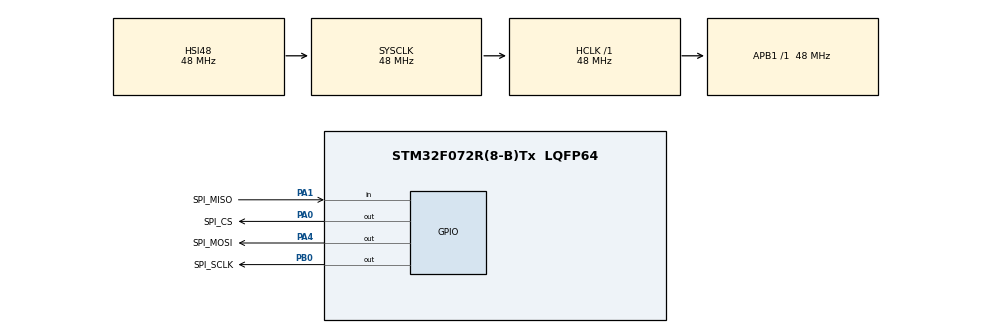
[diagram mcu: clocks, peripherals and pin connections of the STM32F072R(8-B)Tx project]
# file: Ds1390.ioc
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Mcu.Family=STM32F0
Mcu.Name=STM32F072R(8-B)Tx
Mcu.Package=LQFP64
PA0.GPIO_Label=SPI_CS
PA0.GPIO_Speed=GPIO_SPEED_FREQ_HIGH
PA0.PinState=GPIO_PIN_SET
PA0.Signal=GPIO_Output
PA1.GPIO_Label=SPI_MISO
PA1.Signal=GPIO_Input
PA13.Mode=Serial_Wire
PA13.Signal=SYS_SWDIO
PA14.Mode=Serial_Wire
PA14.Signal=SYS_SWCLK
PA4.GPIO_Label=SPI_MOSI
PA4.GPIO_Speed=GPIO_SPEED_FREQ_HIGH
PA4.PinState=GPIO_PIN_SET
PA4.Signal=GPIO_Output
PB0.GPIO_Label=SPI_SCLK
PB0.GPIO_Speed=GPIO_SPEED_FREQ_HIGH
PB0.PinState=GPIO_PIN_SET
PB0.Signal=GPIO_Output
ProjectManager.HeapSize=0x200
ProjectManager.StackSize=0x400
ProjectManager.TargetToolchain=MDK-ARM V5
RCC.AHBFreq_Value=48000000
RCC.APB1Freq_Value=48000000
RCC.APB1TimFreq_Value=48000000
RCC.HCLKFreq_Value=48000000
RCC.SYSCLKFreq_VALUE=48000000
RCC.SYSCLKSource=RCC_SYSCLKSOURCE_HSI48
board=custom

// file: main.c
/* USER CODE BEGIN Header */
/**
  ******************************************************************************
  * @file           : main.c
  * @brief          : Main program body
  ******************************************************************************
  * @attention
  *
  * Copyright (c) 2022 STMicroelectronics.
  * All rights reserved.
  *
  * This software is licensed under terms that can be found in the LICENSE file
  * in the root directory of this software component.
  * If no LICENSE file comes with this software, it is provided AS-IS.
  *
  ******************************************************************************
  */
/* USER CODE END Header */
#include "main.h"
#include "gpio.h"

/* USER CODE BEGIN Includes */
#include "ds1390.h"

/* USER CODE END Includes */

/* USER CODE BEGIN PV */
int Hour,Minute,Second,Saniye=5;
int Day,Month,Year,Dow,Sayi=0;

/* USER CODE END PV */

void SystemClock_Config(void);

int main(void)
{

  /* MCU Configuration--------------------------------------------------------*/

  /* Reset of all peripherals, Initializes the Flash interface and the Systick. */
  HAL_Init();

  /* Configure the system clock */
  SystemClock_Config();

  /* Initialize all configured peripherals */
  MX_GPIO_Init();
  /* USER CODE BEGIN 2 */

  rtc_init();
  //rtc_set_datetime(10,2,22,4,15,13,30);

  /* USER CODE END 2 */

  /* Infinite loop */
  while (1)
  {

    /* USER CODE BEGIN 3 */
    rtc_get_time(&Hour,&Minute,&Second);
    rtc_get_date(&Day,&Month,&Year,&Dow);
    Sayi++;

    HAL_Delay(500);

  }
  /* USER CODE END 3 */
}

void SystemClock_Config(void)
{
  RCC_OscInitTypeDef RCC_OscInitStruct = {0};
  RCC_ClkInitTypeDef RCC_ClkInitStruct = {0};

  /** Initializes the RCC Oscillators according to the specified parameters
  * in the RCC_OscInitTypeDef structure.
  */
  RCC_OscInitStruct.OscillatorType = RCC_OSCILLATORTYPE_HSI48;
  RCC_OscInitStruct.HSI48State = RCC_HSI48_ON;
  RCC_OscInitStruct.PLL.PLLState = RCC_PLL_NONE;
  if (HAL_RCC_OscConfig(&RCC_OscInitStruct) != HAL_OK)
  {
    Error_Handler();
  }
  /** Initializes the CPU, AHB and APB buses clocks
  */
  RCC_ClkInitStruct.ClockType = RCC_CLOCKTYPE_HCLK|RCC_CLOCKTYPE_SYSCLK
                              |RCC_CLOCKTYPE_PCLK1;
  RCC_ClkInitStruct.SYSCLKSource = RCC_SYSCLKSOURCE_HSI48;
  RCC_ClkInitStruct.AHBCLKDivider = RCC_SYSCLK_DIV1;
  RCC_ClkInitStruct.APB1CLKDivider = RCC_HCLK_DIV1;

  if (HAL_RCC_ClockConfig(&RCC_ClkInitStruct, FLASH_LATENCY_1) != HAL_OK)
  {
    Error_Handler();
  }
}

void Error_Handler(void)
{
  __disable_irq();
  while (1)
  {
  }
}
